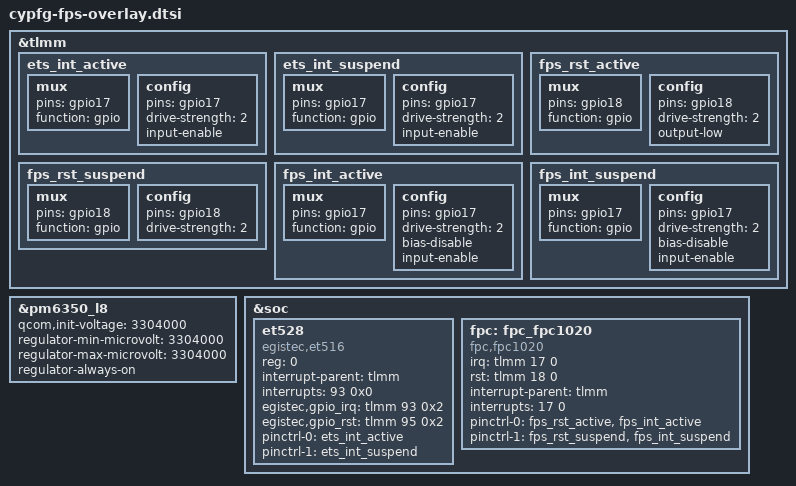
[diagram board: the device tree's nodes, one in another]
&tlmm {
	ets_int_active: ets_int_active {
		/* INTERRUPT */
		mux {
			pins = "gpio17";
			function = "gpio";
		};

		config {
			pins = "gpio17";
			drive-strength = <2>; /* 2 MA */
			input-enable;
		};
	};

	ets_int_suspend: ets_int_suspend {
		/* INTERRUPT */
		mux {
			pins = "gpio17";
			function = "gpio";
		};

		config {
			pins = "gpio17";
			drive-strength = <2>; /* 2 MA */
			input-enable;
		};
	};

	fps_rst_active: fps_rst_active {
		/* active state */
		mux {
			pins = "gpio18";
			function = "gpio";
		};

		config {
			pins = "gpio18";
			drive-strength = <2>; /* 2 MA */
			output-low;
		};
	};

	fps_rst_suspend: fps_rst_suspend {
		/* sleep state */
		mux {
			pins = "gpio18";
			function = "gpio";
		};

		config {
			pins = "gpio18";
			drive-strength = <2>; /* 2 MA */
		};
	};

	fps_int_active: fps_int_active {
		/* active state */
		mux {
			pins = "gpio17";
			function = "gpio";
		};

		config {
			pins = "gpio17";
			drive-strength = <2>; /* 2 MA */
			bias-disable;
			input-enable;
		};
	};

	fps_int_suspend: fps_int_suspend {
		/* sleep state */
		mux {
			pins = "gpio17";
			function = "gpio";
		};

		config {
			pins = "gpio17";
			drive-strength = <2>; /* 2 MA */
			bias-disable;
			input-enable;
		};
	};
};

&pm6350_l8 {
 qcom,init-voltage = <3304000>;
 regulator-min-microvolt = <3304000>;
 regulator-max-microvolt = <3304000>;
 regulator-always-on;
};

&soc {
	et528: et528 {
		compatible = "egistec,et516";
		status = "ok";
		reg = <0>;
		interrupt-parent = <&tlmm>;
		interrupts = <93 0x0>;
		egistec,gpio_irq = <&tlmm 93 0x2>;
		egistec,gpio_rst = <&tlmm 95 0x2>;
		pinctrl-names = "default", "suspend";
		pinctrl-0 = <&ets_int_active>;
		pinctrl-1 = <&ets_int_suspend>;
	};

	fpc: fpc_fpc1020 {
		compatible = "fpc,fpc1020";
		status = "ok";
		irq = <&tlmm 17 0>;
		rst = <&tlmm 18 0>;
		interrupt-parent = <&tlmm>;
		interrupts = <17 0>;
		pinctrl-names = "default", "suspend";
		pinctrl-0 = <&fps_rst_active &fps_int_active>;
		pinctrl-1 = <&fps_rst_suspend &fps_int_suspend>;
	};
};
